AUTOSAR XML (schema 3-1-5)
standard types defined: Boolean, SInt8, UInt8, SInt16, UInt16, UInt32, SInt32, Float
package /rte_simple_lib/CalculatorKit
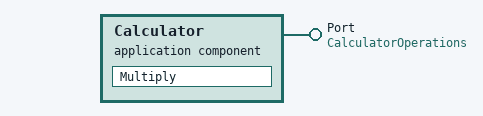
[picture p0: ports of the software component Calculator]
  application software component type Calculator
    provide port Port: provided-interface=CalculatorOperations
  internal behavior CalculatorBehavior: component=Calculator
    operation invoked event InvokeCalculator: start-on-event=Multiply, operation=Port.Multiply
    runnable Multiply: can-be-invoked-concurrently=true
  swc implementation CalculatorImplementation: behavior=CalculatorBehavior
package /rte_simple_lib/Interfaces
  client server interface CalculatorOperations
    operation Multiply
      arg arg1: type=UInt8, direction=IN
      arg arg2: type=UInt8, direction=IN
      arg result: type=UInt16, direction=OUT
  sender receiver interface ArgumentIf
    data arg1: type=UInt8
    data arg2: type=UInt8
  sender receiver interface ResultIf
    data result: type=UInt16
package /rte_simple_lib/TesterKit
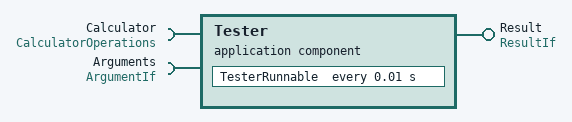
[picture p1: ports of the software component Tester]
  application software component type Tester
    require port Calculator: required-interface=CalculatorOperations
    require port Arguments: required-interface=ArgumentIf
    provide port Result: provided-interface=ResultIf
  internal behavior TesterBehavior: component=Tester
    timing event StepTester: start-on-event=TesterRunnable, period=0.01
    runnable TesterRunnable: can-be-invoked-concurrently=true
      data read access ReadArg1: data-element=Arguments.arg1
      data read access ReadArg2: data-element=Arguments.arg2
      data write access WriteResult: data-element=Result.result
      sync call CallCalculator: operation=Calculator.Multiply
  swc implementation TesterImplementation: behavior=TesterBehavior
